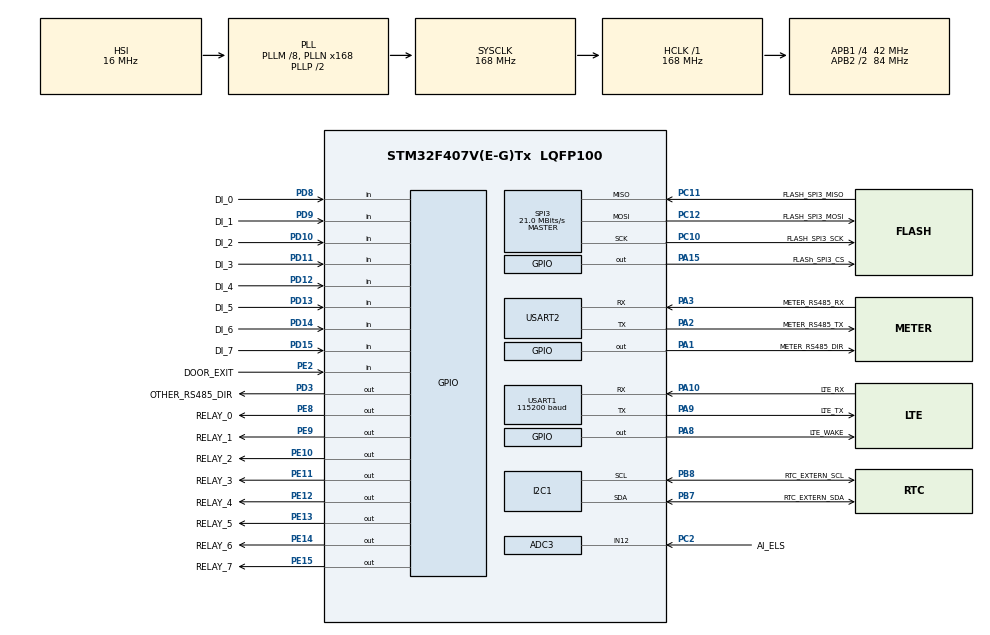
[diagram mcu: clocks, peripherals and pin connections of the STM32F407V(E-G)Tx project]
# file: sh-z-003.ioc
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ADC3.Channel-8\#ChannelRegularConversion=ADC_CHANNEL_12
ADC3.NbrOfConversionFlag=1
ADC3.Rank-8\#ChannelRegularConversion=1
ADC3.SamplingTime-8\#ChannelRegularConversion=ADC_SAMPLETIME_3CYCLES
Dma.Request0=USART1_TX
Dma.USART1_TX.0.Direction=DMA_MEMORY_TO_PERIPH
Dma.USART1_TX.0.FIFOMode=DMA_FIFOMODE_DISABLE
Dma.USART1_TX.0.Instance=DMA2_Stream7
Dma.USART1_TX.0.MemDataAlignment=DMA_MDATAALIGN_BYTE
Dma.USART1_TX.0.MemInc=DMA_MINC_ENABLE
Dma.USART1_TX.0.Mode=DMA_NORMAL
Dma.USART1_TX.0.PeriphDataAlignment=DMA_PDATAALIGN_BYTE
Dma.USART1_TX.0.PeriphInc=DMA_PINC_DISABLE
Dma.USART1_TX.0.Priority=DMA_PRIORITY_MEDIUM
FREERTOS.Tasks01=defaultTask,0,128,StartDefaultTask,Default,NULL,Dynamic,NULL,NULL;lte_tasks,-3,256,start_lte_tasks,As external,NULL,Dynamic,NULL,NULL
FREERTOS.configTOTAL_HEAP_SIZE=32768
Mcu.Family=STM32F4
Mcu.Name=STM32F407V(E-G)Tx
Mcu.Package=LQFP100
NVIC.DMA2_Stream7_IRQn=true\:9\:0\:true\:false\:true\:true\:false
NVIC.PriorityGroup=NVIC_PRIORITYGROUP_4
NVIC.TIM1_UP_TIM10_IRQn=true\:0\:0\:false\:false\:true\:false\:false
NVIC.TimeBase=TIM1_UP_TIM10_IRQn
NVIC.TimeBaseIP=TIM1
NVIC.USART1_IRQn=true\:10\:0\:true\:false\:true\:true\:true
PA1.GPIO_Label=METER_RS485_DIR
PA1.Signal=GPIO_Output
PA10.GPIO_Label=LTE_RX
PA10.Mode=Asynchronous
PA10.Signal=USART1_RX
PA13.Mode=Trace_Asynchronous_SW
PA13.Signal=SYS_JTMS-SWDIO
PA14.Mode=Trace_Asynchronous_SW
PA14.Signal=SYS_JTCK-SWCLK
PA15.GPIO_Label=FLASh_SPI3_CS
PA15.Signal=GPIO_Output
PA2.GPIO_Label=METER_RS485_TX
PA2.Mode=Asynchronous
PA2.Signal=USART2_TX
PA3.GPIO_Label=METER_RS485_RX
PA3.Mode=Asynchronous
PA3.Signal=USART2_RX
PA8.GPIO_Label=LTE_WAKE
PA8.GPIO_ModeDefaultOutputPP=GPIO_MODE_OUTPUT_OD
PA8.GPIO_PuPd=GPIO_PULLUP
PA8.PinState=GPIO_PIN_SET
PA8.Signal=GPIO_Output
PA9.GPIO_Label=LTE_TX
PA9.Mode=Asynchronous
PA9.Signal=USART1_TX
PB3.Mode=Trace_Asynchronous_SW
PB3.Signal=SYS_JTDO-SWO
PB7.GPIO_Label=RTC_EXTERN_SDA
PB7.Mode=I2C
PB7.Signal=I2C1_SDA
PB8.GPIO_Label=RTC_EXTERN_SCL
PB8.Mode=I2C
PB8.Signal=I2C1_SCL
PC10.GPIO_Label=FLASH_SPI3_SCK
PC10.Mode=Full_Duplex_Master
PC10.Signal=SPI3_SCK
PC11.GPIO_Label=FLASH_SPI3_MISO
PC11.Mode=Full_Duplex_Master
PC11.Signal=SPI3_MISO
PC12.GPIO_Label=FLASH_SPI3_MOSI
PC12.Mode=Full_Duplex_Master
PC12.Signal=SPI3_MOSI
PC2.GPIO_Label=AI_ELS
PC2.Signal=ADCx_IN12
PD10.GPIO_Label=DI_2
PD10.Signal=GPIO_Input
PD11.GPIO_Label=DI_3
PD11.Signal=GPIO_Input
PD12.GPIO_Label=DI_4
PD12.Signal=GPIO_Input
PD13.GPIO_Label=DI_5
PD13.Signal=GPIO_Input
PD14.GPIO_Label=DI_6
PD14.Signal=GPIO_Input
PD15.GPIO_Label=DI_7
PD15.Signal=GPIO_Input
PD3.GPIO_Label=OTHER_RS485_DIR
PD3.Signal=GPIO_Output
PD8.GPIO_Label=DI_0
PD8.Signal=GPIO_Input
PD9.GPIO_Label=DI_1
PD9.Signal=GPIO_Input
PE10.GPIO_Label=RELAY_2
PE10.Signal=GPIO_Output
PE11.GPIO_Label=RELAY_3
PE11.Signal=GPIO_Output
PE12.GPIO_Label=RELAY_4
PE12.Signal=GPIO_Output
PE13.GPIO_Label=RELAY_5
PE13.Signal=GPIO_Output
PE14.GPIO_Label=RELAY_6
PE14.Signal=GPIO_Output
PE15.GPIO_Label=RELAY_7
PE15.Signal=GPIO_Output
PE2.GPIO_Label=DOOR_EXIT
PE2.Signal=GPIO_Input
PE8.GPIO_Label=RELAY_0
PE8.Signal=GPIO_Output
PE9.GPIO_Label=RELAY_1
PE9.Signal=GPIO_Output
ProjectManager.HeapSize=0x800
ProjectManager.StackSize=0x800
ProjectManager.TargetToolchain=MDK-ARM V5
RCC.48MHZClocksFreq_Value=84000000
RCC.AHBFreq_Value=168000000
RCC.APB1CLKDivider=RCC_HCLK_DIV4
RCC.APB1Freq_Value=42000000
RCC.APB1TimFreq_Value=84000000
RCC.APB2CLKDivider=RCC_HCLK_DIV2
RCC.APB2Freq_Value=84000000
RCC.APB2TimFreq_Value=168000000
RCC.CortexFreq_Value=168000000
RCC.HCLKFreq_Value=168000000
RCC.HSE_VALUE=8000000
RCC.HSI_VALUE=16000000
RCC.LSE_VALUE=32768
RCC.PLLM=8
RCC.PLLN=168
RCC.SYSCLKFreq_VALUE=168000000
RCC.SYSCLKSource=RCC_SYSCLKSOURCE_PLLCLK
RCC.VCOOutputFreq_Value=336000000
SH.ADCx_IN12.0=ADC3_IN12,IN12
SPI3.CalculateBaudRate=21.0 MBits/s
SPI3.Direction=SPI_DIRECTION_2LINES
SPI3.Mode=SPI_MODE_MASTER
SPI3.VirtualType=VM_MASTER
USART1.BaudRate=115200
USART1.Parity=PARITY_NONE
USART1.VirtualMode=VM_ASYNC
USART1.WordLength=WORDLENGTH_8B
USART2.VirtualMode=VM_ASYNC
VP_FREERTOS_VS_ENABLE.Mode=Enabled
VP_SYS_VS_tim1.Mode=TIM1
board=custom

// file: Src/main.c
/**
  ******************************************************************************
  * @file           : main.c
  * @brief          : Main program body
  ******************************************************************************
  * This notice applies to any and all portions of this file
  * that are not between comment pairs USER CODE BEGIN and
  * USER CODE END. Other portions of this file, whether
  * inserted by the user or by software development tools
  * are owned by their respective copyright owners.
  *
  * Copyright (c) 2018 STMicroelectronics International N.V.
  * All rights reserved.
  *
  * Redistribution and use in source and binary forms, with or without
  * modification, are permitted, provided that the following conditions are met:
  *
  * 1. Redistribution of source code must retain the above copyright notice,
  *    this list of conditions and the following disclaimer.
  * 2. Redistributions in binary form must reproduce the above copyright notice,
  *    this list of conditions and the following disclaimer in the documentation
  *    and/or other materials provided with the distribution.
  * 3. Neither the name of STMicroelectronics nor the names of other
  *    contributors to this software may be used to endorse or promote products
  *    derived from this software without specific written permission.
  * 4. This software, including modifications and/or derivative works of this
  *    software, must execute solely and exclusively on microcontroller or
  *    microprocessor devices manufactured by or for STMicroelectronics.
  * 5. Redistribution and use of this software other than as permitted under
  *    this license is void and will automatically terminate your rights under
  *    this license.
  *
  * THIS SOFTWARE IS PROVIDED BY STMICROELECTRONICS AND CONTRIBUTORS "AS IS"
  * AND ANY EXPRESS, IMPLIED OR STATUTORY WARRANTIES, INCLUDING, BUT NOT
  * LIMITED TO, THE IMPLIED WARRANTIES OF MERCHANTABILITY, FITNESS FOR A
  * PARTICULAR PURPOSE AND NON-INFRINGEMENT OF THIRD PARTY INTELLECTUAL PROPERTY
  * RIGHTS ARE DISCLAIMED TO THE FULLEST EXTENT PERMITTED BY LAW. IN NO EVENT
  * SHALL STMICROELECTRONICS OR CONTRIBUTORS BE LIABLE FOR ANY DIRECT, INDIRECT,
  * INCIDENTAL, SPECIAL, EXEMPLARY, OR CONSEQUENTIAL DAMAGES (INCLUDING, BUT NOT
  * LIMITED TO, PROCUREMENT OF SUBSTITUTE GOODS OR SERVICES; LOSS OF USE, DATA,
  * OR PROFITS; OR BUSINESS INTERRUPTION) HOWEVER CAUSED AND ON ANY THEORY OF
  * LIABILITY, WHETHER IN CONTRACT, STRICT LIABILITY, OR TORT (INCLUDING
  * NEGLIGENCE OR OTHERWISE) ARISING IN ANY WAY OUT OF THE USE OF THIS SOFTWARE,
  * EVEN IF ADVISED OF THE POSSIBILITY OF SUCH DAMAGE.
  *
  ******************************************************************************
  */
#include "main.h"
#include "stm32f4xx_hal.h"
#include "cmsis_os.h"

ADC_HandleTypeDef hadc3;

I2C_HandleTypeDef hi2c1;

SPI_HandleTypeDef hspi3;

UART_HandleTypeDef huart1;
UART_HandleTypeDef huart2;
DMA_HandleTypeDef hdma_usart1_tx;

osThreadId defaultTaskHandle;
osThreadId lte_tasksHandle;

/* USER CODE BEGIN PV */
/* Private variables ---------------------------------------------------------*/

/* USER CODE END PV */

void SystemClock_Config(void);
static void MX_GPIO_Init(void);
static void MX_DMA_Init(void);
static void MX_USART1_UART_Init(void);
static void MX_SPI3_Init(void);
static void MX_ADC3_Init(void);
static void MX_I2C1_Init(void);
static void MX_USART2_UART_Init(void);
void StartDefaultTask(void const * argument);
extern void start_lte_tasks(void const * argument);

/* USER CODE BEGIN PFP */
/* Private function prototypes -----------------------------------------------*/

/* USER CODE END PFP */

int main(void)
{

  /* MCU Configuration----------------------------------------------------------*/

  /* Reset of all peripherals, Initializes the Flash interface and the Systick. */
  HAL_Init();

  /* Configure the system clock */
  SystemClock_Config();

  /* Initialize all configured peripherals */
  MX_GPIO_Init();
  MX_DMA_Init();
  MX_USART1_UART_Init();
  MX_SPI3_Init();
  MX_ADC3_Init();
  MX_I2C1_Init();
  MX_USART2_UART_Init();

  /* Create the thread(s) */
  /* definition and creation of defaultTask */
  osThreadDef(defaultTask, StartDefaultTask, osPriorityNormal, 0, 128);
  defaultTaskHandle = osThreadCreate(osThread(defaultTask), NULL);

  /* definition and creation of lte_tasks */
  osThreadDef(lte_tasks, start_lte_tasks, osPriorityIdle, 0, 256);
  lte_tasksHandle = osThreadCreate(osThread(lte_tasks), NULL);

  /* Start scheduler */
  osKernelStart();

  /* We should never get here as control is now taken by the scheduler */

  /* Infinite loop */
  while (1)
  {

  }

}

void SystemClock_Config(void)
{

  RCC_OscInitTypeDef RCC_OscInitStruct;
  RCC_ClkInitTypeDef RCC_ClkInitStruct;

    /**Configure the main internal regulator output voltage
    */
  __HAL_RCC_PWR_CLK_ENABLE();

  __HAL_PWR_VOLTAGESCALING_CONFIG(PWR_REGULATOR_VOLTAGE_SCALE1);

    /**Initializes the CPU, AHB and APB busses clocks
    */
  RCC_OscInitStruct.OscillatorType = RCC_OSCILLATORTYPE_HSI;
  RCC_OscInitStruct.HSIState = RCC_HSI_ON;
  RCC_OscInitStruct.HSICalibrationValue = 16;
  RCC_OscInitStruct.PLL.PLLState = RCC_PLL_ON;
  RCC_OscInitStruct.PLL.PLLSource = RCC_PLLSOURCE_HSI;
  RCC_OscInitStruct.PLL.PLLM = 8;
  RCC_OscInitStruct.PLL.PLLN = 168;
  RCC_OscInitStruct.PLL.PLLP = RCC_PLLP_DIV2;
  RCC_OscInitStruct.PLL.PLLQ = 4;
  if (HAL_RCC_OscConfig(&RCC_OscInitStruct) != HAL_OK)
  {
    _Error_Handler(__FILE__, __LINE__);
  }

    /**Initializes the CPU, AHB and APB busses clocks
    */
  RCC_ClkInitStruct.ClockType = RCC_CLOCKTYPE_HCLK|RCC_CLOCKTYPE_SYSCLK
                              |RCC_CLOCKTYPE_PCLK1|RCC_CLOCKTYPE_PCLK2;
  RCC_ClkInitStruct.SYSCLKSource = RCC_SYSCLKSOURCE_PLLCLK;
  RCC_ClkInitStruct.AHBCLKDivider = RCC_SYSCLK_DIV1;
  RCC_ClkInitStruct.APB1CLKDivider = RCC_HCLK_DIV4;
  RCC_ClkInitStruct.APB2CLKDivider = RCC_HCLK_DIV2;

  if (HAL_RCC_ClockConfig(&RCC_ClkInitStruct, FLASH_LATENCY_5) != HAL_OK)
  {
    _Error_Handler(__FILE__, __LINE__);
  }

    /**Configure the Systick interrupt time
    */
  HAL_SYSTICK_Config(HAL_RCC_GetHCLKFreq()/1000);

    /**Configure the Systick
    */
  HAL_SYSTICK_CLKSourceConfig(SYSTICK_CLKSOURCE_HCLK);

  /* SysTick_IRQn interrupt configuration */
  HAL_NVIC_SetPriority(SysTick_IRQn, 15, 0);
}

/* ADC3 init function */
static void MX_ADC3_Init(void)
{

  ADC_ChannelConfTypeDef sConfig;

    /**Configure the global features of the ADC (Clock, Resolution, Data Alignment and number of conversion)
    */
  hadc3.Instance = ADC3;
  hadc3.Init.ClockPrescaler = ADC_CLOCK_SYNC_PCLK_DIV4;
  hadc3.Init.Resolution = ADC_RESOLUTION_12B;
  hadc3.Init.ScanConvMode = DISABLE;
  hadc3.Init.ContinuousConvMode = DISABLE;
  hadc3.Init.DiscontinuousConvMode = DISABLE;
  hadc3.Init.ExternalTrigConvEdge = ADC_EXTERNALTRIGCONVEDGE_NONE;
  hadc3.Init.ExternalTrigConv = ADC_SOFTWARE_START;
  hadc3.Init.DataAlign = ADC_DATAALIGN_RIGHT;
  hadc3.Init.NbrOfConversion = 1;
  hadc3.Init.DMAContinuousRequests = DISABLE;
  hadc3.Init.EOCSelection = ADC_EOC_SINGLE_CONV;
  if (HAL_ADC_Init(&hadc3) != HAL_OK)
  {
    _Error_Handler(__FILE__, __LINE__);
  }

    /**Configure for the selected ADC regular channel its corresponding rank in the sequencer and its sample time.
    */
  sConfig.Channel = ADC_CHANNEL_12;
  sConfig.Rank = 1;
  sConfig.SamplingTime = ADC_SAMPLETIME_3CYCLES;
  if (HAL_ADC_ConfigChannel(&hadc3, &sConfig) != HAL_OK)
  {
    _Error_Handler(__FILE__, __LINE__);
  }

}

/* I2C1 init function */
static void MX_I2C1_Init(void)
{

  hi2c1.Instance = I2C1;
  hi2c1.Init.ClockSpeed = 100000;
  hi2c1.Init.DutyCycle = I2C_DUTYCYCLE_2;
  hi2c1.Init.OwnAddress1 = 0;
  hi2c1.Init.AddressingMode = I2C_ADDRESSINGMODE_7BIT;
  hi2c1.Init.DualAddressMode = I2C_DUALADDRESS_DISABLE;
  hi2c1.Init.OwnAddress2 = 0;
  hi2c1.Init.GeneralCallMode = I2C_GENERALCALL_DISABLE;
  hi2c1.Init.NoStretchMode = I2C_NOSTRETCH_DISABLE;
  if (HAL_I2C_Init(&hi2c1) != HAL_OK)
  {
    _Error_Handler(__FILE__, __LINE__);
  }

}

/* SPI3 init function */
static void MX_SPI3_Init(void)
{

  /* SPI3 parameter configuration*/
  hspi3.Instance = SPI3;
  hspi3.Init.Mode = SPI_MODE_MASTER;
  hspi3.Init.Direction = SPI_DIRECTION_2LINES;
  hspi3.Init.DataSize = SPI_DATASIZE_8BIT;
  hspi3.Init.CLKPolarity = SPI_POLARITY_LOW;
  hspi3.Init.CLKPhase = SPI_PHASE_1EDGE;
  hspi3.Init.NSS = SPI_NSS_SOFT;
  hspi3.Init.BaudRatePrescaler = SPI_BAUDRATEPRESCALER_2;
  hspi3.Init.FirstBit = SPI_FIRSTBIT_MSB;
  hspi3.Init.TIMode = SPI_TIMODE_DISABLE;
  hspi3.Init.CRCCalculation = SPI_CRCCALCULATION_DISABLE;
  hspi3.Init.CRCPolynomial = 10;
  if (HAL_SPI_Init(&hspi3) != HAL_OK)
  {
    _Error_Handler(__FILE__, __LINE__);
  }

}

/* USART1 init function */
static void MX_USART1_UART_Init(void)
{

  huart1.Instance = USART1;
  huart1.Init.BaudRate = 115200;
  huart1.Init.WordLength = UART_WORDLENGTH_8B;
  huart1.Init.StopBits = UART_STOPBITS_1;
  huart1.Init.Parity = UART_PARITY_NONE;
  huart1.Init.Mode = UART_MODE_TX_RX;
  huart1.Init.HwFlowCtl = UART_HWCONTROL_NONE;
  huart1.Init.OverSampling = UART_OVERSAMPLING_16;
  if (HAL_UART_Init(&huart1) != HAL_OK)
  {
    _Error_Handler(__FILE__, __LINE__);
  }

}

/* USART2 init function */
static void MX_USART2_UART_Init(void)
{

  huart2.Instance = USART2;
  huart2.Init.BaudRate = 115200;
  huart2.Init.WordLength = UART_WORDLENGTH_8B;
  huart2.Init.StopBits = UART_STOPBITS_1;
  huart2.Init.Parity = UART_PARITY_NONE;
  huart2.Init.Mode = UART_MODE_TX_RX;
  huart2.Init.HwFlowCtl = UART_HWCONTROL_NONE;
  huart2.Init.OverSampling = UART_OVERSAMPLING_16;
  if (HAL_UART_Init(&huart2) != HAL_OK)
  {
    _Error_Handler(__FILE__, __LINE__);
  }

}

static void MX_DMA_Init(void)
{
  /* DMA controller clock enable */
  __HAL_RCC_DMA2_CLK_ENABLE();

  /* DMA interrupt init */
  /* DMA2_Stream7_IRQn interrupt configuration */
  HAL_NVIC_SetPriority(DMA2_Stream7_IRQn, 9, 0);
  HAL_NVIC_EnableIRQ(DMA2_Stream7_IRQn);

}

/** Configure pins as
        * Analog
        * Input
        * Output
        * EVENT_OUT
        * EXTI
*/
static void MX_GPIO_Init(void)
{

  GPIO_InitTypeDef GPIO_InitStruct;

  /* GPIO Ports Clock Enable */
  __HAL_RCC_GPIOE_CLK_ENABLE();
  __HAL_RCC_GPIOC_CLK_ENABLE();
  __HAL_RCC_GPIOA_CLK_ENABLE();
  __HAL_RCC_GPIOD_CLK_ENABLE();
  __HAL_RCC_GPIOB_CLK_ENABLE();

  /*Configure GPIO pin Output Level */
  HAL_GPIO_WritePin(GPIOA, METER_RS485_DIR_Pin|FLASh_SPI3_CS_Pin, GPIO_PIN_RESET);

  /*Configure GPIO pin Output Level */
  HAL_GPIO_WritePin(GPIOE, RELAY_0_Pin|RELAY_1_Pin|RELAY_2_Pin|RELAY_3_Pin
                          |RELAY_4_Pin|RELAY_5_Pin|RELAY_6_Pin|RELAY_7_Pin, GPIO_PIN_RESET);

  /*Configure GPIO pin Output Level */
  HAL_GPIO_WritePin(LTE_WAKE_GPIO_Port, LTE_WAKE_Pin, GPIO_PIN_SET);

  /*Configure GPIO pin Output Level */
  HAL_GPIO_WritePin(OTHER_RS485_DIR_GPIO_Port, OTHER_RS485_DIR_Pin, GPIO_PIN_RESET);

  /*Configure GPIO pin : DOOR_EXIT_Pin */
  GPIO_InitStruct.Pin = DOOR_EXIT_Pin;
  GPIO_InitStruct.Mode = GPIO_MODE_INPUT;
  GPIO_InitStruct.Pull = GPIO_NOPULL;
  HAL_GPIO_Init(DOOR_EXIT_GPIO_Port, &GPIO_InitStruct);

  /*Configure GPIO pins : METER_RS485_DIR_Pin FLASh_SPI3_CS_Pin */
  GPIO_InitStruct.Pin = METER_RS485_DIR_Pin|FLASh_SPI3_CS_Pin;
  GPIO_InitStruct.Mode = GPIO_MODE_OUTPUT_PP;
  GPIO_InitStruct.Pull = GPIO_NOPULL;
  GPIO_InitStruct.Speed = GPIO_SPEED_FREQ_LOW;
  HAL_GPIO_Init(GPIOA, &GPIO_InitStruct);

  /*Configure GPIO pins : RELAY_0_Pin RELAY_1_Pin RELAY_2_Pin RELAY_3_Pin
                           RELAY_4_Pin RELAY_5_Pin RELAY_6_Pin RELAY_7_Pin */
  GPIO_InitStruct.Pin = RELAY_0_Pin|RELAY_1_Pin|RELAY_2_Pin|RELAY_3_Pin
                          |RELAY_4_Pin|RELAY_5_Pin|RELAY_6_Pin|RELAY_7_Pin;
  GPIO_InitStruct.Mode = GPIO_MODE_OUTPUT_PP;
  GPIO_InitStruct.Pull = GPIO_NOPULL;
  GPIO_InitStruct.Speed = GPIO_SPEED_FREQ_LOW;
  HAL_GPIO_Init(GPIOE, &GPIO_InitStruct);

  /*Configure GPIO pins : DI_0_Pin DI_1_Pin DI_2_Pin DI_3_Pin
                           DI_4_Pin DI_5_Pin DI_6_Pin DI_7_Pin */
  GPIO_InitStruct.Pin = DI_0_Pin|DI_1_Pin|DI_2_Pin|DI_3_Pin
                          |DI_4_Pin|DI_5_Pin|DI_6_Pin|DI_7_Pin;
  GPIO_InitStruct.Mode = GPIO_MODE_INPUT;
  GPIO_InitStruct.Pull = GPIO_NOPULL;
  HAL_GPIO_Init(GPIOD, &GPIO_InitStruct);

  /*Configure GPIO pin : LTE_WAKE_Pin */
  GPIO_InitStruct.Pin = LTE_WAKE_Pin;
  GPIO_InitStruct.Mode = GPIO_MODE_OUTPUT_OD;
  GPIO_InitStruct.Pull = GPIO_PULLUP;
  GPIO_InitStruct.Speed = GPIO_SPEED_FREQ_LOW;
  HAL_GPIO_Init(LTE_WAKE_GPIO_Port, &GPIO_InitStruct);

  /*Configure GPIO pin : OTHER_RS485_DIR_Pin */
  GPIO_InitStruct.Pin = OTHER_RS485_DIR_Pin;
  GPIO_InitStruct.Mode = GPIO_MODE_OUTPUT_PP;
  GPIO_InitStruct.Pull = GPIO_NOPULL;
  GPIO_InitStruct.Speed = GPIO_SPEED_FREQ_LOW;
  HAL_GPIO_Init(OTHER_RS485_DIR_GPIO_Port, &GPIO_InitStruct);

}

/* StartDefaultTask function */
void StartDefaultTask(void const * argument)
{

  /* USER CODE BEGIN 5 */
  /* Infinite loop */
  for(;;)
  {
    osDelay(1000);
  }
  /* USER CODE END 5 */
}

void HAL_TIM_PeriodElapsedCallback(TIM_HandleTypeDef *htim)
{
  if (htim->Instance == TIM1) {
    HAL_IncTick();
  }
}

void _Error_Handler(char *file, int line)
{
  while(1)
  {
  }
}

/************************ (C) COPYRIGHT STMicroelectronics *****END OF FILE****/
